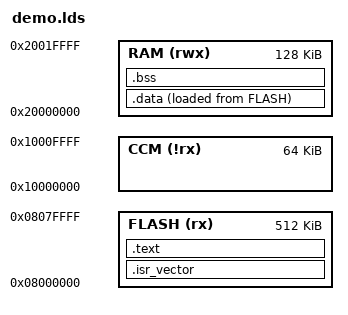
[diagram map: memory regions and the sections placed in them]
/* Demo script for the documentation screenshots: completion, hover, highlighting. */
OUTPUT_FORMAT(elf32-littlearm)
OUTPUT_ARCH(arm)
ENTRY(Reset_Handler)

MEMORY
{
    FLASH (rx)  : ORIGIN = 0x08000000, LENGTH = 512K
    RAM   (rwx) : ORIGIN = 0x20000000, LENGTH = 128K
    CCM   (!rx) : ORIGIN = 0x10000000, LENGTH = 64K
}

PHDRS
{
    text PT_LOAD FILEHDR PHDRS FLAGS(5);
    data PT_LOAD FLAGS(6);
}

SECTIONS
{
    .isr_vector :
    {
        KEEP(*(.isr_vector))
    } > FLASH

    .text :
    {
        *(.text*)
        *(.rodata*)
        BY
        . = ALIGN(4);
    } > FLASH

    .data :
    {
        _sdata = .;
        *(.data*)
        _edata = .;
    } > RAM AT> FLASH

    .bss (NOLOAD) :
    {
        _sbss = .;
        *(.bss*)
        *(COMMON)
        _ebss = .;
    } > RAM

    ASSERT(_ebss <= ORIGIN(RAM) + LENGTH(RAM), "RAM overflow")
}

PROVIDE(__stack_top = ORIGIN(RAM) + LENGTH(RAM));
